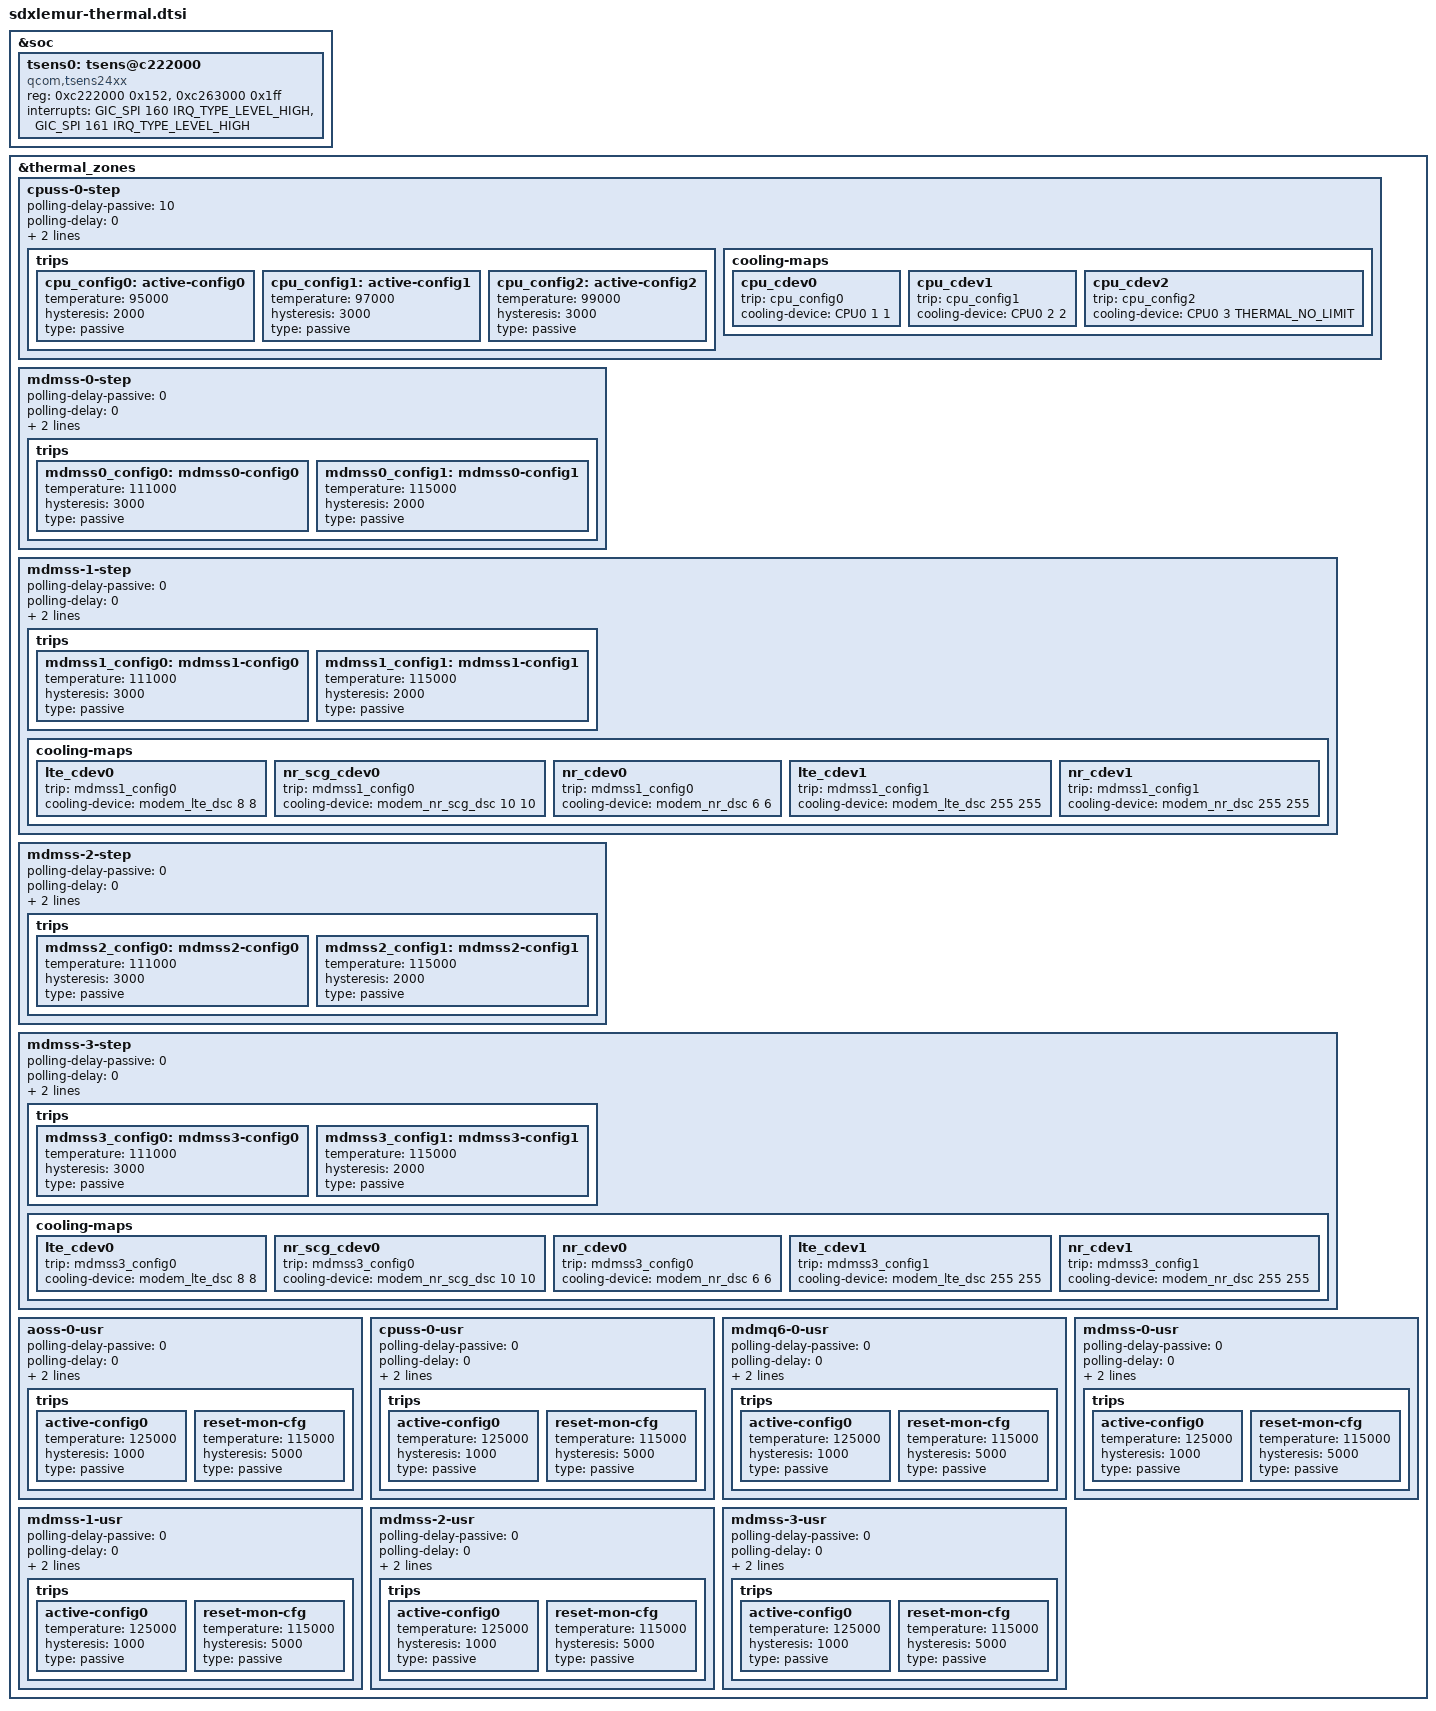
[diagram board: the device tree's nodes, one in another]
#include <dt-bindings/thermal/thermal_qti.h>

&soc {
	tsens0: tsens@c222000 {
		compatible = "qcom,tsens24xx";
		reg = <0xc222000 0x152>,
			<0xc263000 0x1ff>;
		reg-names = "tsens_srot_physical",
				"tsens_tm_physical";
		interrupts = <GIC_SPI 160 IRQ_TYPE_LEVEL_HIGH>,
				<GIC_SPI 161 IRQ_TYPE_LEVEL_HIGH>;
		interrupt-names = "tsens-upper-lower", "tsens-critical";
		#thermal-sensor-cells = <1>;
	};
};

#include "sdxlemur-thermal-modem.dtsi"

&thermal_zones {
	cpuss-0-step {
		polling-delay-passive = <10>;
		polling-delay = <0>;
		thermal-governor = "step_wise";
		thermal-sensors = <&tsens0 1>;
		trips {
			cpu_config0: active-config0 {
				temperature = <95000>;
				hysteresis = <2000>;
				type = "passive";
			};

			cpu_config1: active-config1 {
				temperature = <97000>;
				hysteresis = <3000>;
				type = "passive";
			};

			cpu_config2: active-config2 {
				temperature = <99000>;
				hysteresis = <3000>;
				type = "passive";
			};
		};

		cooling-maps {
			cpu_cdev0 {
				trip = <&cpu_config0>;
				cooling-device = <&CPU0 1 1>;
			};

			cpu_cdev1 {
				trip = <&cpu_config1>;
				cooling-device = <&CPU0 2 2>;
			};

			cpu_cdev2 {
				trip = <&cpu_config2>;
				cooling-device = <&CPU0 3 THERMAL_NO_LIMIT>;
			};
		};
	};

	mdmss-0-step {
		polling-delay-passive = <0>;
		polling-delay = <0>;
		thermal-governor = "step_wise";
		thermal-sensors = <&tsens0 3>;
		trips {
			mdmss0_config0: mdmss0-config0 {
				temperature = <111000>;
				hysteresis = <3000>;
				type = "passive";
			};

			mdmss0_config1: mdmss0-config1 {
				temperature = <115000>;
				hysteresis = <2000>;
				type = "passive";
			};
		};
	};

	mdmss-1-step {
		polling-delay-passive = <0>;
		polling-delay = <0>;
		thermal-governor = "step_wise";
		thermal-sensors = <&tsens0 4>;
		trips {
			mdmss1_config0: mdmss1-config0 {
				temperature = <111000>;
				hysteresis = <3000>;
				type = "passive";
			};

			mdmss1_config1: mdmss1-config1 {
				temperature = <115000>;
				hysteresis = <2000>;
				type = "passive";
			};
		};

		cooling-maps {
			lte_cdev0 {
				trip = <&mdmss1_config0>;
				cooling-device = <&modem_lte_dsc 8 8>;
			};

			nr_scg_cdev0 {
				trip = <&mdmss1_config0>;
				cooling-device = <&modem_nr_scg_dsc 10 10>;
			};

			nr_cdev0 {
				trip = <&mdmss1_config0>;
				cooling-device = <&modem_nr_dsc 6 6>;
			};

			lte_cdev1 {
				trip = <&mdmss1_config1>;
				cooling-device = <&modem_lte_dsc 255 255>;
			};

			nr_cdev1 {
				trip = <&mdmss1_config1>;
				cooling-device = <&modem_nr_dsc 255 255>;
			};
		};
	};

	mdmss-2-step {
		polling-delay-passive = <0>;
		polling-delay = <0>;
		thermal-governor = "step_wise";
		thermal-sensors = <&tsens0 5>;
		trips {
			mdmss2_config0: mdmss2-config0 {
				temperature = <111000>;
				hysteresis = <3000>;
				type = "passive";
			};

			mdmss2_config1: mdmss2-config1 {
				temperature = <115000>;
				hysteresis = <2000>;
				type = "passive";
			};
		};
	};

	mdmss-3-step {
		polling-delay-passive = <0>;
		polling-delay = <0>;
		thermal-governor = "step_wise";
		thermal-sensors = <&tsens0 6>;
		trips {
			mdmss3_config0: mdmss3-config0 {
				temperature = <111000>;
				hysteresis = <3000>;
				type = "passive";
			};

			mdmss3_config1: mdmss3-config1 {
				temperature = <115000>;
				hysteresis = <2000>;
				type = "passive";
			};
		};

		cooling-maps {
			lte_cdev0 {
				trip = <&mdmss3_config0>;
				cooling-device = <&modem_lte_dsc 8 8>;
			};

			nr_scg_cdev0 {
				trip = <&mdmss3_config0>;
				cooling-device = <&modem_nr_scg_dsc 10 10>;
			};

			nr_cdev0 {
				trip = <&mdmss3_config0>;
				cooling-device = <&modem_nr_dsc 6 6>;
			};

			lte_cdev1 {
				trip = <&mdmss3_config1>;
				cooling-device = <&modem_lte_dsc 255 255>;
			};

			nr_cdev1 {
				trip = <&mdmss3_config1>;
				cooling-device = <&modem_nr_dsc 255 255>;
			};
		};
	};

	aoss-0-usr {
		polling-delay-passive = <0>;
		polling-delay = <0>;
		thermal-governor = "user_space";
		thermal-sensors = <&tsens0 0>;
		trips {
			active-config0 {
				temperature = <125000>;
				hysteresis = <1000>;
				type = "passive";
			};

			reset-mon-cfg {
				temperature = <115000>;
				hysteresis = <5000>;
				type = "passive";
			};
		};
	};

	cpuss-0-usr {
		polling-delay-passive = <0>;
		polling-delay = <0>;
		thermal-governor = "user_space";
		thermal-sensors = <&tsens0 1>;
		trips {
			active-config0 {
				temperature = <125000>;
				hysteresis = <1000>;
				type = "passive";
			};

			reset-mon-cfg {
				temperature = <115000>;
				hysteresis = <5000>;
				type = "passive";
			};
		};
	};

	mdmq6-0-usr {
		polling-delay-passive = <0>;
		polling-delay = <0>;
		thermal-governor = "user_space";
		thermal-sensors = <&tsens0 2>;
		trips {
			active-config0 {
				temperature = <125000>;
				hysteresis = <1000>;
				type = "passive";
			};

			reset-mon-cfg {
				temperature = <115000>;
				hysteresis = <5000>;
				type = "passive";
			};
		};
	};

	mdmss-0-usr {
		polling-delay-passive = <0>;
		polling-delay = <0>;
		thermal-governor = "user_space";
		thermal-sensors = <&tsens0 3>;
		trips {
			active-config0 {
				temperature = <125000>;
				hysteresis = <1000>;
				type = "passive";
			};

			reset-mon-cfg {
				temperature = <115000>;
				hysteresis = <5000>;
				type = "passive";
			};
		};
	};

	mdmss-1-usr {
		polling-delay-passive = <0>;
		polling-delay = <0>;
		thermal-governor = "user_space";
		thermal-sensors = <&tsens0 4>;
		trips {
			active-config0 {
				temperature = <125000>;
				hysteresis = <1000>;
				type = "passive";
			};

			reset-mon-cfg {
				temperature = <115000>;
				hysteresis = <5000>;
				type = "passive";
			};
		};
	};

	mdmss-2-usr {
		polling-delay-passive = <0>;
		polling-delay = <0>;
		thermal-governor = "user_space";
		thermal-sensors = <&tsens0 5>;
		trips {
			active-config0 {
				temperature = <125000>;
				hysteresis = <1000>;
				type = "passive";
			};

			reset-mon-cfg {
				temperature = <115000>;
				hysteresis = <5000>;
				type = "passive";
			};
		};
	};

	mdmss-3-usr {
		polling-delay-passive = <0>;
		polling-delay = <0>;
		thermal-governor = "user_space";
		thermal-sensors = <&tsens0 6>;
		trips {
			active-config0 {
				temperature = <125000>;
				hysteresis = <1000>;
				type = "passive";
			};

			reset-mon-cfg {
				temperature = <115000>;
				hysteresis = <5000>;
				type = "passive";
			};
		};
	};
};
